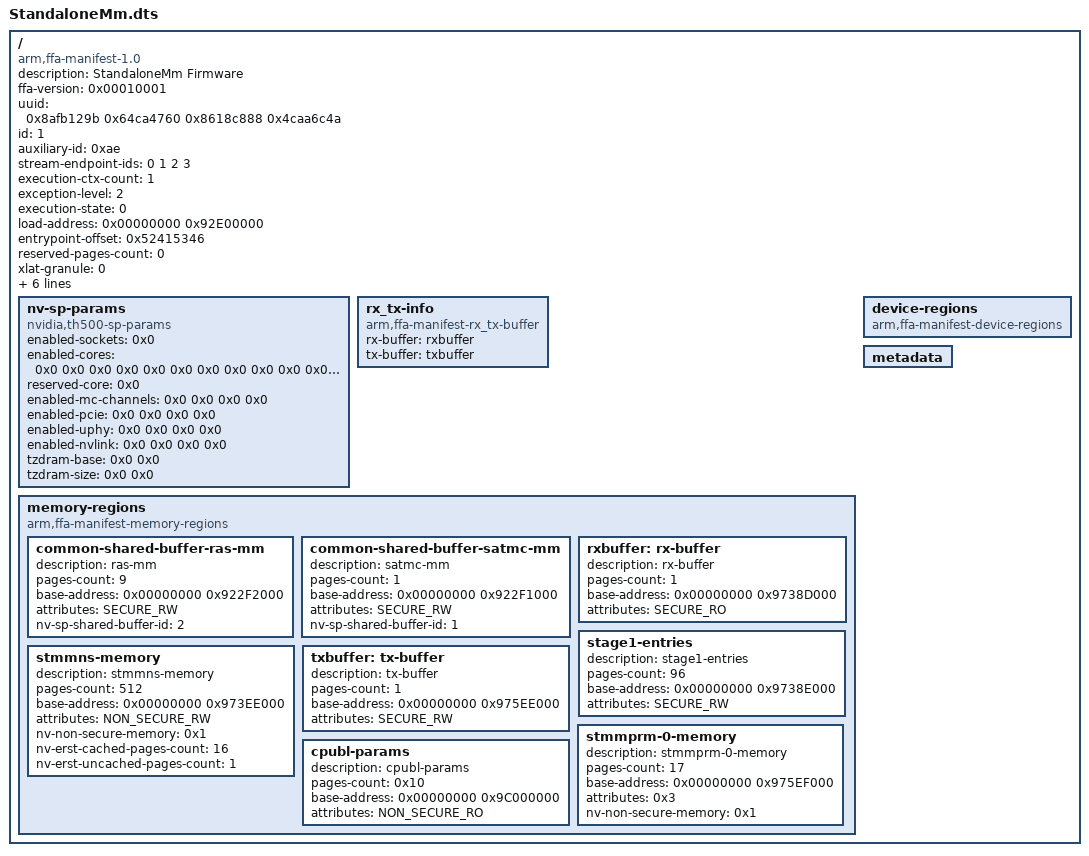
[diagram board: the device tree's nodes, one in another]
/*
 * SPDX-FileCopyrightText: Copyright (c) 2022 - 2025 NVIDIA CORPORATION & AFFILIATES. All rights reserved.
 *
 * SPDX-License-Identifier: BSD-3-Clause
 *
 * Partition manifest for the StMM Secure Partition
 *
 */

/dts-v1/;

/ {
#define SECURE_RO		0x1
#define SECURE_RW		0x3
#define SECURE_EXECUTE_RO 	0x5
#define SECURE_EXECUTE_RW 	0x7
#define NON_SECURE_RO 		0x9
#define NON_SECURE_RW 		0xB
#define NON_SECURE_EXECUTE_RO 	0xD
#define NON_SECURE_EXECUTE_RW 	0xF

	compatible = "arm,ffa-manifest-1.0";

	/* Properties */
	description = "StandaloneMm Firmware";
	ffa-version = <0x00010001>; /* 31:16 - Major, 15:0 - Minor */
	uuid = <0x8afb129b 0x64ca4760 0x8618c888 0x4caa6c4a>;
	id = <1>;
	auxiliary-id = <0xae>;
	stream-endpoint-ids = <0 1 2 3>;
	execution-ctx-count = <1>;
	exception-level = <2>; /* S-EL1 */
	execution-state = <0>; /* AARCH64 */
	load-address = <0x00000000 0x92E00000>;
	entrypoint-offset = <0x52415346>; /* Magic value to get sptool.py to patch it */
	reserved-pages-count = <0>;
	xlat-granule = <0>; /* 4KiB */
	boot-order = <0>;
	messaging-method = <3>; /* Direct messaging with managed exit */
	run-time-model = <0>; /* Run to completion */
	ns-interrupts-action = <0>; /* Non-secure interrupt is queued */
	other-s-interrupts-action = <0>; /* Other-Secure interrupt is queued */

	/* Boot protocol */
	gp-register-num = <0x0>;

	nv-sp-params {
		compatible = "nvidia,th500-sp-params";
		enabled-sockets = <0x0>;
		enabled-cores = <0x0 0x0 0x0 0x0
				0x0 0x0 0x0 0x0
				0x0 0x0 0x0 0x0
				0x0 0x0 0x0 0x0>;
		reserved-core = <0x0>;
		enabled-mc-channels = <0x0 0x0 0x0 0x0>;
		enabled-pcie = <0x0 0x0 0x0 0x0>;
		enabled-uphy = <0x0 0x0 0x0 0x0>;
		enabled-nvlink = <0x0 0x0 0x0 0x0>;
		tzdram-base = <0x0 0x0>;
		tzdram-size = <0x0 0x0>;
	};

	rx_tx-info {
		compatible = "arm,ffa-manifest-rx_tx-buffer";
		rx-buffer = <&rxbuffer>;
		tx-buffer = <&txbuffer>;
	};

	memory-regions {
		compatible = "arm,ffa-manifest-memory-regions";

		/*
		 * Regions will either be allocated by MB2 at the end of the SP space, or
		 * outside of SP space.
		 */
		/* Buffer for shared communication from RAS_FW to MM */
		common-shared-buffer-ras-mm {
			description = "ras-mm";
			pages-count = <9>;
			base-address = <0x00000000 0x922F2000>;
			attributes = <SECURE_RW>; /* read-write */
			nv-sp-shared-buffer-id = <2>;
		};
		/* Buffer for shared communication from SATMC to MM */
		common-shared-buffer-satmc-mm {
			description = "satmc-mm";
			pages-count = <1>;
			base-address = <0x00000000 0x922F1000>;
			attributes = <SECURE_RW>; /* read-write */
			nv-sp-shared-buffer-id = <1>;
		};
		rxbuffer: rx-buffer {
			description = "rx-buffer";
			pages-count = <1>;
			base-address = <0x00000000 0x9738D000>;
			attributes = <SECURE_RO>; /* read-only */
		};
		/* Reserved memory for stage-1 table entries */
		stage1-entries {
			description = "stage1-entries";
			pages-count = <96>;
			base-address = <0x00000000 0x9738E000>;
			attributes = <SECURE_RW>; /* read-write */
		};
		/* Shared memory between StMM and NS world */
		stmmns-memory {
			description = "stmmns-memory";
			pages-count = <512>;
			base-address = <0x00000000 0x973EE000>;
			attributes = <NON_SECURE_RW>; /* read-write */
			nv-non-secure-memory = <0x1>;
			nv-erst-cached-pages-count = <16>;
			nv-erst-uncached-pages-count = <1>;
		};
		txbuffer: tx-buffer {
			description = "tx-buffer";
			pages-count = <1>;
			base-address = <0x00000000 0x975EE000>;
			attributes = <SECURE_RW>; /* read-write */
		};
		stmmprm-0-memory {
			description = "stmmprm-0-memory";
			pages-count = <17>;
			base-address = <0x00000000 0x975EF000>;
			attributes = <0x3>; /* read-write */
			nv-non-secure-memory = <0x1>;
		};
		cpubl-params {
			description  = "cpubl-params";
			pages-count  = < 0x10 >;
			base-address = < 0x00000000 0x9C000000 >;
			attributes   = <NON_SECURE_RO>; /* read-only */
		};
	};

	device-regions {
		compatible = "arm,ffa-manifest-device-regions";
		#include "StmmDeviceRegions.dtsi"
	};

	metadata {
	};
};
